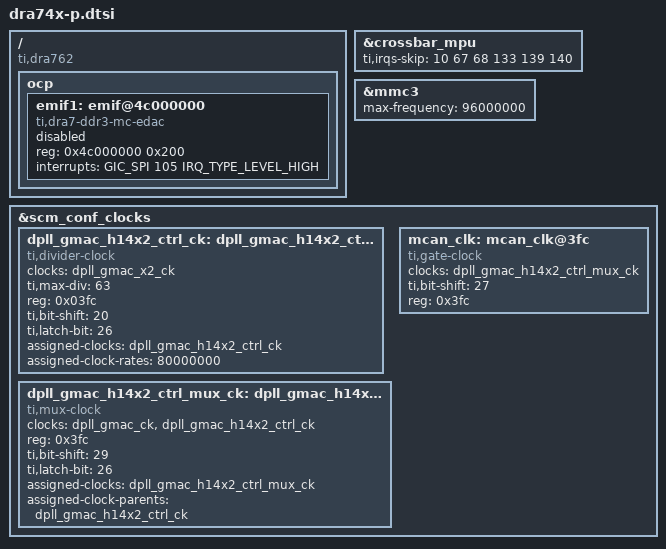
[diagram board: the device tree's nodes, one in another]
/*
 * Copyright (C) 2017 Texas Instruments Incorporated - http://www.ti.com/
 *
 * This program is free software; you can redistribute it and/or modify
 * it under the terms of the GNU General Public License version 2 as
 * published by the Free Software Foundation.
 */

#include "dra74x.dtsi"

/ {
	compatible = "ti,dra762", "ti,dra7";

	ocp {
		emif1: emif@4c000000 {
			compatible = "ti,dra7-ddr3-mc-edac";
			reg = <0x4c000000 0x200>;
			interrupts = <GIC_SPI 105 IRQ_TYPE_LEVEL_HIGH>;
			status = "disabled";
		};
	};
};

/* MCAN interrupts are hard-wired to irqs 67, 68 */
&crossbar_mpu {
	ti,irqs-skip = <10 67 68 133 139 140>;
};

&mmc3 {
	max-frequency = <96000000>;
};

&scm_conf_clocks {
	dpll_gmac_h14x2_ctrl_ck: dpll_gmac_h14x2_ctrl_ck@3fc {
		#clock-cells = <0>;
		compatible = "ti,divider-clock";
		clocks = <&dpll_gmac_x2_ck>;
		ti,max-div = <63>;
		reg = <0x03fc>;
		ti,bit-shift=<20>;
		ti,latch-bit=<26>;
		assigned-clocks = <&dpll_gmac_h14x2_ctrl_ck>;
		assigned-clock-rates = <80000000>;
	};

	dpll_gmac_h14x2_ctrl_mux_ck: dpll_gmac_h14x2_ctrl_mux_ck@3fc {
		#clock-cells = <0>;
		compatible = "ti,mux-clock";
		clocks = <&dpll_gmac_ck>, <&dpll_gmac_h14x2_ctrl_ck>;
		reg = <0x3fc>;
		ti,bit-shift = <29>;
		ti,latch-bit=<26>;
		assigned-clocks = <&dpll_gmac_h14x2_ctrl_mux_ck>;
		assigned-clock-parents = <&dpll_gmac_h14x2_ctrl_ck>;
	};

	mcan_clk: mcan_clk@3fc {
		#clock-cells = <0>;
		compatible = "ti,gate-clock";
		clocks = <&dpll_gmac_h14x2_ctrl_mux_ck>;
		ti,bit-shift = <27>;
		reg = <0x3fc>;
	};
};
